AUTOSAR XML (schema 4-0-3)
standard types defined: Boolean, UInt32
package /AUTOSAR_Platform/DataConstrs
  range DC_Boolean: raw 0..1
package /PATAC/MSM/ComponentTypes
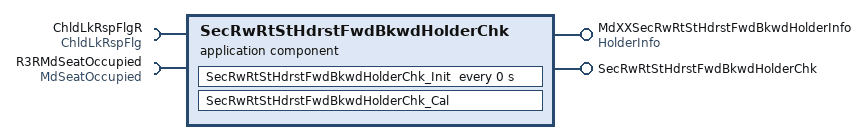
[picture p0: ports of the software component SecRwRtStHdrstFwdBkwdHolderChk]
  application sw component type SecRwRtStHdrstFwdBkwdHolderChk
    provide port MdXXSecRwRtStHdrstFwdBkwdHolderInfo: nonqueued-sender-com-spec{data-element=HolderInfo/Val, init-value=0}, provided-interface=HolderInfo
    provide port SecRwRtStHdrstFwdBkwdHolderChk: server-com-spec{operation=Cal, queue-length=1}, provided-interface=SecRwRtStHdrstFwdBkwdHolderChk
    require port ChldLkRspFlgR: nonqueued-receiver-com-spec{data-element=ChldLkRspFlg/Val, filter=data-filter-type=ALWAYS, init-value=0}, required-interface=ChldLkRspFlg
    require port R3RMdSeatOccupied: nonqueued-receiver-com-spec{data-element=MdSeatOccupied/Val, filter=data-filter-type=ALWAYS, init-value=0}, required-interface=MdSeatOccupied
    behavior SecRwRtStHdrstFwdBkwdHolderChk_InternalBehavior
      operation invoked event OIT_SecRwRtStHdrstFwdBkwdHolderChk_Cal_SecRwRtStHdrstFwdBkwdHolderChk_Cal: start-on-event=SecRwRtStHdrstFwdBkwdHolderChk_Cal, operation=SecRwRtStHdrstFwdBkwdHolderChk.Cal
      timing event SecRwRtStHdrstFwdBkwdHolderChk_InitEvent: start-on-event=SecRwRtStHdrstFwdBkwdHolderChk_Init, period=0
      runnable SecRwRtStHdrstFwdBkwdHolderChk_Cal
        data-receive-point-by-arguments:
          access REC_ChldLkRspFlgR_Val: accessed-variable=ChldLkRspFlgR.Val
          access REC_R3RMdSeatOccupied_Val: accessed-variable=R3RMdSeatOccupied.Val
        data-send-points:
          access SEND_MdXXSecRwRtStHdrstFwdBkwdHolderInfo_Val: accessed-variable=MdXXSecRwRtStHdrstFwdBkwdHolderInfo.Val
      runnable SecRwRtStHdrstFwdBkwdHolderChk_Init
  swc implementation SecRwRtStHdrstFwdBkwdHolderChk_Implementation: behavior=SecRwRtStHdrstFwdBkwdHolderChk_InternalBehavior
    code-descriptors:
      code Default: artifact-descriptors=autosar-engineering-object={short-label=Default, category=SWSRC}
package /PATAC/MSM/ModeAdjust/PortInterface
  client server interface SecRwRtStHdrstFwdBkwdHolderChk
    operation Cal
  sender receiver interface ChldLkRspFlg: invalidation-policy{data-element=ChldLkRspFlg/Val, handle-invalid=DONT-INVALIDATE}
    data Val: type=Boolean
  sender receiver interface HolderInfo: invalidation-policy{data-element=HolderInfo/Val, handle-invalid=DONT-INVALIDATE}
    data Val: type=UInt32
  sender receiver interface MdSeatOccupied: invalidation-policy{data-element=MdSeatOccupied/Val, handle-invalid=DONT-INVALIDATE}
    data Val: type=Boolean
